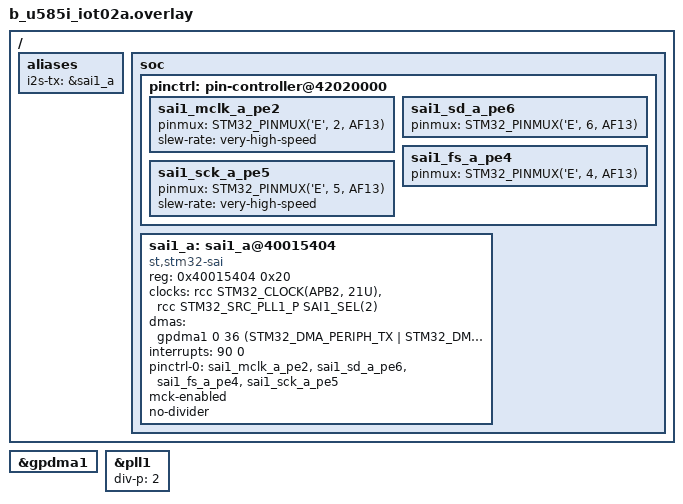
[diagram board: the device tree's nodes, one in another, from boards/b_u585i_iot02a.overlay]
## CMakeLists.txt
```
# SPDX-License-Identifier: Apache-2.0

cmake_minimum_required(VERSION 3.28.0)

find_package(Zephyr REQUIRED HINTS $ENV{ZEPHYR_BASE})
project(i2s_output)

target_sources(app PRIVATE src/main.c)
```

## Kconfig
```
# Copyright (c) 2026 Mario Paja
# SPDX-License-Identifier: Apache-2.0

config SAMPLE_I2S_OPT_BIT_CLK_GATED
	bool "Run I2S bit clock only while sending data"
	default y if SOC_FAMILY_STM32
	default y if I2S_SILABS_USART
	help
	  Enable I2S bit clock (BCLK) so that it runs
	  only while audio data is actively being transmitted.

config SAMPLE_I2S_FORMAT_PDM
	bool "Transmit with the PDM data format"
	help
	  Configure the stream with I2S_FMT_DATA_FORMAT_PDM instead of
	  I2S_FMT_DATA_FORMAT_I2S.

config HEAP_MEM_POOL_ADD_SIZE_SAMPLE
	int
	default 256 if SOC_FAMILY_STM32 && I2S_STM32_SAI

source "Kconfig.zephyr"
```

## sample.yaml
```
sample:
  description: I2S Output Sample
  name: i2s_output
common:
  tags:
    - drivers
    - i2s
tests:
  sample.drivers.i2s.output:
    filter: dt_alias_exists("i2s-tx")
    integration_platforms:
      - mimxrt1060_evk@B/mimxrt1062/qspi
      - mimxrt1060_evk@C/mimxrt1062/qspi
      - mimxrt700_evk/mimxrt798s/cm33_cpu0
      - mimxrt1170_evk/mimxrt1176/cm7
      - mimxrt1180_evk/mimxrt1189/cm33
      - mimxrt1180_evk/mimxrt1189/cm7
    extra_configs:
      - CONFIG_DMA_TCD_QUEUE_SIZE=4
    harness: console
    harness_config:
      type: one_line
      regex:
        - "All I2S blocks written"
```

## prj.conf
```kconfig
CONFIG_AUDIO=y
CONFIG_I2S=y
```

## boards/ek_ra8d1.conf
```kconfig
#
# Copyright (c) 2025 Renesas Electronics Corporation
#
# SPDX-License-Identifier: Apache-2.0
#

CONFIG_PWM=y
CONFIG_CLOCK_CONTROL=y
CONFIG_I2S_INIT_PRIORITY=52
CONFIG_CLOCK_CONTROL_FIXED_RATE_CLOCK=y
```

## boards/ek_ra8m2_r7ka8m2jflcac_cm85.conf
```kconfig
# Copyright (c) 2025 Renesas Electronics Corporation
# SPDX-License-Identifier: Apache-2.0

CONFIG_I2S_INIT_PRIORITY=52
```

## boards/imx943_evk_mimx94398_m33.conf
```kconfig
#
# Copyright 2025 NXP
#
# SPDX-License-Identifier: Apache-2.0
#
CONFIG_DMA_TCD_QUEUE_SIZE=4
```

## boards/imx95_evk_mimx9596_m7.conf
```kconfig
# Copyright 2026 NXP
# SPDX-License-Identifier: Apache-2.0

# Enable nocache memory for DMA descriptors
CONFIG_NOCACHE_MEMORY=y

# Disable PLL setting as imx95 uses SCMI for clock management
CONFIG_I2S_HAS_PLL_SETTING=n

# Raise DMA TCD Queue size, as this is required by the I2S SAI driver
CONFIG_DMA_TCD_QUEUE_SIZE=4
CONFIG_GPIO=y
CONFIG_GPIO_PCAL64XXA=y
```

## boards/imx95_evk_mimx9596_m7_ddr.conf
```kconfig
# Copyright 2026 NXP
# SPDX-License-Identifier: Apache-2.0

# Enable nocache memory for DMA descriptors
CONFIG_NOCACHE_MEMORY=y

# Disable PLL setting as imx95 uses SCMI for clock management
CONFIG_I2S_HAS_PLL_SETTING=n

CONFIG_GPIO=y
CONFIG_GPIO_PCAL64XXA=y
CONFIG_GPIO_HOGS=y
```

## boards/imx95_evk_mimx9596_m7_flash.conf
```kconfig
# Copyright 2026 NXP
# SPDX-License-Identifier: Apache-2.0

# Enable nocache memory for DMA descriptors
CONFIG_NOCACHE_MEMORY=y

# Disable PLL setting as imx95 uses SCMI for clock management
CONFIG_I2S_HAS_PLL_SETTING=n

CONFIG_GPIO=y
CONFIG_GPIO_PCAL64XXA=y
```

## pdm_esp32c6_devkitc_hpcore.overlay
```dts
/* Copyright (c) 2026 Espressif Systems (Shanghai) Co., Ltd.
 *
 * SPDX-License-Identifier: Apache-2.0
 */

&i2s_default {
	group2 {
		pinmux = <I2S_O_SD_GPIO11>;
		output-invert;
	};
};
```

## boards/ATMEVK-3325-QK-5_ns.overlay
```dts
&i2s {
	sck-out-pin = <18>;
	ws-out-pin = <19>;
	sd-out-pin = <20>;
	status = "okay";
};

/ {
	aliases {
		i2s-tx = &i2s;
	};
};
```

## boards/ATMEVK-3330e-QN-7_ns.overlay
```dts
&i2s {
	status = "okay";
};

/ {
	aliases {
		i2s-tx = &i2s;
	};
};
```

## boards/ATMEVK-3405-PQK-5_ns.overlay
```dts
&i2s {
	sck-out-pin = <3>;
	ws-out-pin = <4>;
	sd-out-pin = <5>;
	status = "okay";
};

/ {
	aliases {
		i2s-tx = &i2s;
	};
};
```

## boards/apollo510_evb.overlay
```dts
/*
 * Copyright (c) 2026 Ambiq Micro Inc.
 *
 * SPDX-License-Identifier: Apache-2.0
 */
/ {
	aliases {
		i2s-tx = &i2s0;
	};
};

&i2s0 {
	status = "okay";
};
```

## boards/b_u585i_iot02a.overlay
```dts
/ {
	aliases {
		i2s-tx = &sai1_a;
	};

	soc {
		pinctrl: pin-controller@42020000 {
			/omit-if-no-ref/ sai1_mclk_a_pe2: sai1_mclk_a_pe2 {
				pinmux = <STM32_PINMUX('E', 2, AF13)>;
				slew-rate = "very-high-speed";
			};
			/omit-if-no-ref/ sai1_sd_a_pe6: sai1_sd_a_pe6 {
				pinmux = <STM32_PINMUX('E', 6, AF13)>;
			};
			/omit-if-no-ref/ sai1_fs_a_pe4: sai1_fs_a_pe4 {
				pinmux = <STM32_PINMUX('E', 4, AF13)>;
			};
			/omit-if-no-ref/ sai1_sck_a_pe5: sai1_sck_a_pe5 {
				pinmux = <STM32_PINMUX('E', 5, AF13)>;
				slew-rate = "very-high-speed";
			};
		};

		sai1_a: sai1_a@40015404 {
			compatible = "st,stm32-sai";
			#address-cells = <1>;
			#size-cells = <0>;
			reg = <0x40015404 0x20>;
			clocks = <&rcc STM32_CLOCK(APB2, 21U)>,
			         <&rcc STM32_SRC_PLL1_P SAI1_SEL(2)>;
			dmas = <&gpdma1 0 36 (STM32_DMA_PERIPH_TX | STM32_DMA_PRIORITY_HIGH)>;
			dma-names = "tx";
			interrupts = <90 0>;
			status = "disabled";
		};

		/* SAI1_B - Not Tested */
		/*
		sai1_b: sai1_b@40015424 {
			compatible = "st,stm32-sai";
			#address-cells = <1>;
			#size-cells = <0>;
			reg = <0x40015424 0x20>;
			clocks = <&rcc STM32_CLOCK(APB2, 21U)>,
			         <&rcc STM32_SRC_PLL1_P SAI1_SEL(2)>;
			dmas = <&gpdma1 0 37 (STM32_DMA_PERIPH_TX | STM32_DMA_PRIORITY_HIGH)
			&gpdma1 1 37 (STM32_DMA_PERIPH_RX | STM32_DMA_PRIORITY_HIGH)>;
			dma-names = "tx", "rx";
			interrupts = <90 0>;
			status = "disabled";
		};
		 */
	};

};

&sai1_a {
	pinctrl-0 = <&sai1_mclk_a_pe2 &sai1_sd_a_pe6
	&sai1_fs_a_pe4 &sai1_sck_a_pe5>;
	pinctrl-names = "default";
	status = "okay";
	mck-enabled;
	no-divider;
};

&gpdma1 {
	status = "okay";
};

&pll1 {
	div-p = <2>;
};
```

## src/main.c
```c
/*
 * Copyright 2023 NXP
 *
 * SPDX-License-Identifier: Apache-2.0
 */

#include <stdio.h>
#include <zephyr/kernel.h>
#include <zephyr/drivers/i2s.h>
#include <zephyr/sys/iterable_sections.h>

#define SAMPLE_NO 64

/* The data represent a sine wave */
static int16_t data[SAMPLE_NO] = {
	  3211,   6392,   9511,  12539,  15446,  18204,  20787,  23169,
	 25329,  27244,  28897,  30272,  31356,  32137,  32609,  32767,
	 32609,  32137,  31356,  30272,  28897,  27244,  25329,  23169,
	 20787,  18204,  15446,  12539,   9511,   6392,   3211,      0,
	 -3212,  -6393,  -9512, -12540, -15447, -18205, -20788, -23170,
	-25330, -27245, -28898, -30273, -31357, -32138, -32610, -32767,
	-32610, -32138, -31357, -30273, -28898, -27245, -25330, -23170,
	-20788, -18205, -15447, -12540,  -9512,  -6393,  -3212,     -1,
};

/* Fill buffer with sine wave on left channel, and sine wave shifted by
 * 90 degrees on right channel. "att" represents a power of two to attenuate
 * the samples by
 */
static void fill_buf(int16_t *tx_block, int att)
{
	int r_idx;

	for (int i = 0; i < SAMPLE_NO; i++) {
		/* Left channel is sine wave */
		tx_block[2 * i] = data[i] / (1 << att);
		/* Right channel is same sine wave, shifted by 90 degrees */
		r_idx = (i + (ARRAY_SIZE(data) / 4)) % ARRAY_SIZE(data);
		tx_block[2 * i + 1] = data[r_idx] / (1 << att);
	}
}

#define NUM_BLOCKS 20
#define BLOCK_SIZE (2 * sizeof(data))

#ifdef CONFIG_NOCACHE_MEMORY
	#define MEM_SLAB_CACHE_ATTR __nocache
#else
	#define MEM_SLAB_CACHE_ATTR
#endif /* CONFIG_NOCACHE_MEMORY */

static char MEM_SLAB_CACHE_ATTR __aligned(WB_UP(32))
	_k_mem_slab_buf_tx_0_mem_slab[(NUM_BLOCKS) * WB_UP(BLOCK_SIZE)];

static STRUCT_SECTION_ITERABLE(k_mem_slab, tx_0_mem_slab) =
	Z_MEM_SLAB_INITIALIZER(tx_0_mem_slab, _k_mem_slab_buf_tx_0_mem_slab,
				WB_UP(BLOCK_SIZE), NUM_BLOCKS);

int main(void)
{
	void *tx_block[NUM_BLOCKS];
	struct i2s_config i2s_cfg;
	int ret;
	uint32_t tx_idx;
	const struct device *dev_i2s = DEVICE_DT_GET(DT_ALIAS(i2s_tx));

	if (!device_is_ready(dev_i2s)) {
		printf("I2S device not ready\n");
		return -ENODEV;
	}
	/* Configure I2S stream */
	i2s_cfg.word_size = 16U;
	i2s_cfg.channels = 2U;
	i2s_cfg.format = IS_ENABLED(CONFIG_SAMPLE_I2S_FORMAT_PDM) ? I2S_FMT_DATA_FORMAT_PDM
								  : I2S_FMT_DATA_FORMAT_I2S;
	i2s_cfg.frame_clk_freq = 44100;
	i2s_cfg.block_size = BLOCK_SIZE;
	i2s_cfg.timeout = 2000;
	/* Configure the Transmit port as Controller */
	i2s_cfg.options = I2S_OPT_FRAME_CLK_CONTROLLER | I2S_OPT_BIT_CLK_CONTROLLER
#ifdef CONFIG_SAMPLE_I2S_OPT_BIT_CLK_GATED
			  | I2S_OPT_BIT_CLK_GATED
#endif
		;
	i2s_cfg.mem_slab = &tx_0_mem_slab;
	ret = i2s_configure(dev_i2s, I2S_DIR_TX, &i2s_cfg);
	if (ret < 0) {
		printf("Failed to configure I2S stream\n");
		return ret;
	}

	/* Prepare all TX blocks */
	for (tx_idx = 0; tx_idx < NUM_BLOCKS; tx_idx++) {
		ret = k_mem_slab_alloc(&tx_0_mem_slab, &tx_block[tx_idx],
				       K_FOREVER);
		if (ret < 0) {
			printf("Failed to allocate TX block\n");
			return ret;
		}
		fill_buf((uint16_t *)tx_block[tx_idx], tx_idx % 3);
	}

	tx_idx = 0;
	/* Send first block */
	ret = i2s_write(dev_i2s, tx_block[tx_idx++], BLOCK_SIZE);
	if (ret < 0) {
		printf("Could not write TX buffer %d\n", tx_idx);
		return ret;
	}
	/* Trigger the I2S transmission */
	ret = i2s_trigger(dev_i2s, I2S_DIR_TX, I2S_TRIGGER_START);
	if (ret < 0) {
		printf("Could not trigger I2S tx\n");
		return ret;
	}

	for (; tx_idx < NUM_BLOCKS; ) {
		ret = i2s_write(dev_i2s, tx_block[tx_idx++], BLOCK_SIZE);
		if (ret < 0) {
			printf("Could not write TX buffer %d\n", tx_idx);
			return ret;
		}
	}
	/* Drain TX queue */
	ret = i2s_trigger(dev_i2s, I2S_DIR_TX, I2S_TRIGGER_DRAIN);
	if (ret < 0) {
		printf("Could not trigger I2S tx\n");
		return ret;
	}
	printf("All I2S blocks written\n");
	return 0;
}
```
